# nrf9120_mlm1 register map
Vendor: Nordic Semiconductor; Series: nrf91; File version: 1
CPU: CM4 r0p1, little endian, MPU, FPU, 3 interrupt priority bits
Registers are 32-bit, read-write, reset 0x0 unless marked. A register's access mark holds for its fields unless they carry their own. Offsets are from the block's base; [hi:lo] are bit positions; lines under a group give offsets from that group; {n}, {i} and the like mark numbered series; 'fields as' and 'values as' point back to an identical list.

## DCNF — Domain Configuration Management
Base 0x40000000; alternate view of AMLI
0x420 CPUID ro — CPU number in the system
  [7:0] CPUID
0x440 EXTPERI0 group — Unspecified
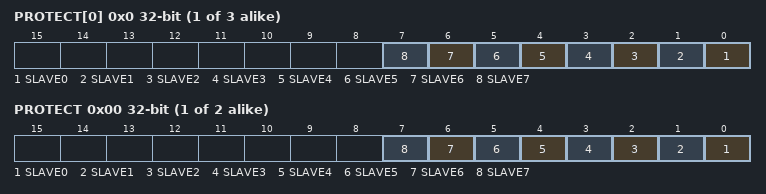
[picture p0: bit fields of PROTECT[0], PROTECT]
  {0x0+4j} PROTECT[{j}] (j=0..2) — Description collection: Control access for Master connected to AMLI master port EXTPERI[n]
    [all] fields
      0=Allowed (Access to slave is possible); 1=Blocked (Access to slave is blocked)
    [n] SLAVE{n} (n=0..7) — Control access to slave {n} of master EXTPERI[n].
0x460 EXTRAM group — Unspecified
  {0x0+4j} PROTECT[{j}] (j=0..2) — Description collection: Control access from Master connected to AMLI master port EXTRAM[n]
    [all] fields
      values as the fields of EXTPERI0.PROTECT[0]
    [n] SLAVE{n} (n=0..7) — Control access to slave {n} of master EXTRAM[n].
{0x480+4i} EXTCODE[{i}] (i=0..1) group — Unspecified
  0x00 PROTECT — Description cluster: Control access from Master connected to AMLI master port EXTCODE[n]
    [all] fields
      values as the fields of EXTPERI0.PROTECT[0]
    [n] SLAVE{n} (n=0..7) — Control access to slave {n} of master EXTCODE[n].

## GPIO — GPIO Port
Base 0x40800000
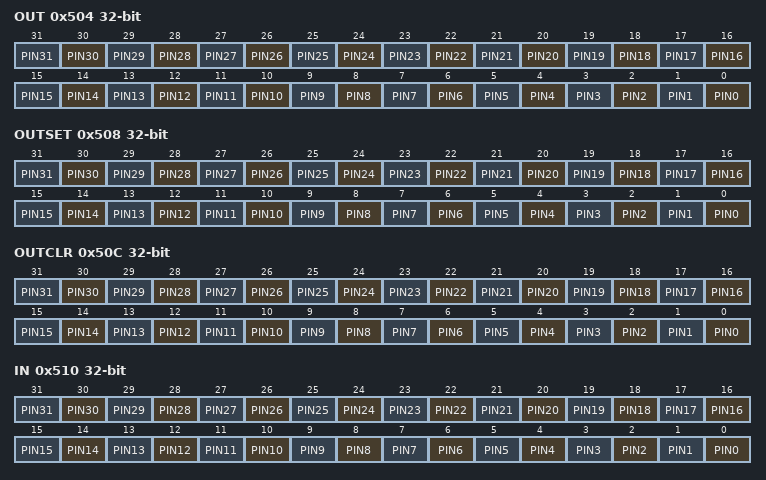
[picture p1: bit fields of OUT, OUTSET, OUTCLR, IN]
0x504 OUT — Write GPIO port
  [all] fields
    0=Low (Pin driver is low); 1=High (Pin driver is high)
  [n] PIN{n} (n=0..31)
0x508 OUTSET write-1-sets — Set individual bits in GPIO port
  [all] fields
    on read: 0=Low (Read: pin driver is low); 1=High (Read: pin driver is high) | on write: 1=Set (Write: writing a '1' sets the pin high; writing a '0' has no effect)
  [n] PIN{n} (n=0..31)
0x50C OUTCLR write-1-clears — Clear individual bits in GPIO port
  [all] fields
    on read: 0=Low (Read: pin driver is low); 1=High (Read: pin driver is high) | on write: 1=Clear (Write: writing a '1' sets the pin low; writing a '0' has no effect)
  [n] PIN{n} (n=0..31)
0x510 IN ro — Read GPIO port
  [all] fields
    0=Low (Pin input is low); 1=High (Pin input is high)
  [n] PIN{n} (n=0..31)
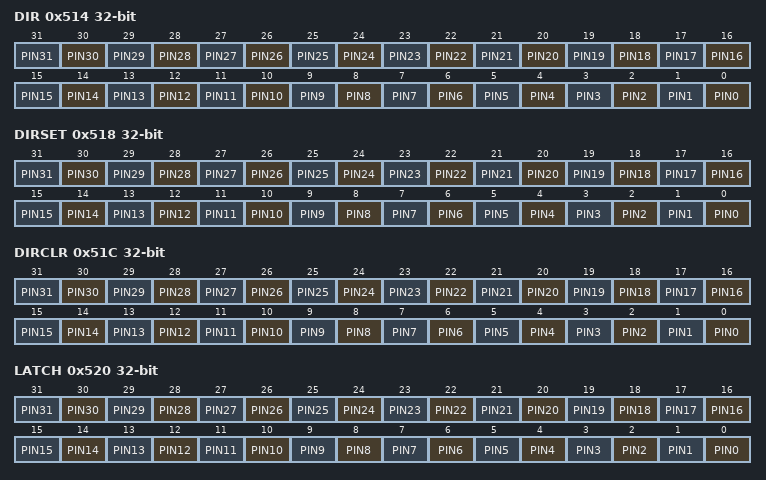
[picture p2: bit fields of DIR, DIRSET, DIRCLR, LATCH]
0x514 DIR — Direction of GPIO pins
  [all] fields
    0=Input (Pin set as input); 1=Output (Pin set as output)
  [n] PIN{n} (n=0..31)
0x518 DIRSET write-1-sets
  [all] fields
    on read: 0=Input (Read: pin set as input); 1=Output (Read: pin set as output) | on write: 1=Set (Write: writing a '1' sets pin to output; writing a '0' has no effect)
  [n] PIN{n} (n=0..31) — Set as output pin {n}
0x51C DIRCLR write-1-clears — DIR clear register
  [all] fields
    on read: 0=Input (Read: pin set as input); 1=Output (Read: pin set as output) | on write: 1=Clear (Write: writing a '1' sets pin to input; writing a '0' has no effect)
  [n] PIN{n} (n=0..31) — Set as input pin {n}
0x520 LATCH — Latch register indicating what GPIO pins that have met the criteria set in the PIN_CNF[n].SENSE registers
  [all] fields
    0=NotLatched (Criteria has not been met); 1=Latched (Criteria has been met)
  [n] PIN{n} (n=0..31) — Status on whether PIN{n} has met criteria set in PIN_CNF{n}.SENSE register. Write '1' to clear.
0x524 DETECTMODE — Select between default DETECT signal behaviour and LDETECT mode
  [0] DETECTMODE
    0=Default (DETECT directly connected to PIN DETECT signals); 1=LDETECT (Use the latched LDETECT behaviour)
{0x600+8i} PIN[{i}] (i=0..31) group — Pin n direct access
  0x00 OUT — Description cluster: Pin n direct access output register
    [0] OUT — Direct access
  0x04 IN — Description cluster: Pin n direct access input register
    [0] IN — Direct access
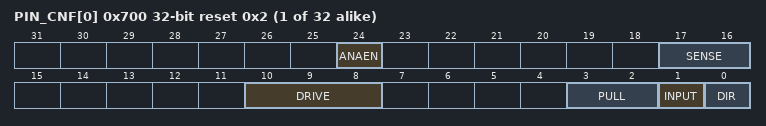
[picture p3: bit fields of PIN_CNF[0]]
{0x700+4i} PIN_CNF[{i}] (i=0..31) reset 0x2 — Description collection: Configuration of GPIO pins
  [24] ANAEN — Override of analog mux enable signals for pads with analog functionality
    0=Disabled (Override of analog mux is disabled); 1=AE0 (Enable analog signal 0 (analog test bus))
  [17:16] SENSE — Pin sensing mechanism
    0=Disabled; 2=High (Sense for high level); 3=Low (Sense for low level)
  [10:8] DRIVE — Drive configuration
    0=S0S1 (Standard '0', standard '1'); 1=H0S1 (High drive '0', standard '1'); 2=S0H1 (Standard '0', high drive '1'); 3=H0H1 (High drive '0', high 'drive '1''); 4=D0S1 (Disconnect '0' standard '1' (normally used for wired-or connections)); 5=D0H1 (Disconnect '0', high drive '1' (normally used for wired-or connections)); 6=S0D1 (Standard '0'. disconnect '1' (normally used for wired-and connections)); 7=H0D1 (High drive '0', disconnect '1' (normally used for wired-and connections))
  [3:2] PULL — Pull configuration
    0=Disabled (No pull); 1=Pull down on pin; 3=Pull up on pin
  [1] INPUT — Connect or disconnect input buffer
    0=Connect input buffer; 1=Disconnect input buffer
  [0] DIR — Pin direction. Same physical register as DIR register
    0=Input (Configure pin as an input pin); 1=Output (Configure pin as an output pin)

## Notices in the file
Copyright (c) 2016, Nordic Semiconductor ASA
All rights reserved.
Redistribution and use in source and binary forms, with or without
modification, are permitted provided that the following conditions are met:
Redistributions of source code must retain the above copyright notice, this
list of conditions and the following disclaimer.
Redistributions in binary form must reproduce the above copyright notice,
this list of conditions and the following disclaimer in the documentation
and/or other materials provided with the distribution.
Neither the name of Nordic Semiconductor ASA nor the names of its
contributors may be used to endorse or promote products derived from
this software without specific prior written permission.
THIS SOFTWARE IS PROVIDED BY THE COPYRIGHT HOLDERS AND CONTRIBUTORS "AS IS"
AND ANY EXPRESS OR IMPLIED WARRANTIES, INCLUDING, BUT NOT LIMITED TO, THE
IMPLIED WARRANTIES OF MERCHANTABILITY AND FITNESS FOR A PARTICULAR PURPOSE ARE
DISCLAIMED. IN NO EVENT SHALL THE COPYRIGHT HOLDER OR CONTRIBUTORS BE LIABLE
FOR ANY DIRECT, INDIRECT, INCIDENTAL, SPECIAL, EXEMPLARY, OR CONSEQUENTIAL
DAMAGES (INCLUDING, BUT NOT LIMITED TO, PROCUREMENT OF SUBSTITUTE GOODS OR
SERVICES; LOSS OF USE, DATA, OR PROFITS; OR BUSINESS INTERRUPTION) HOWEVER
CAUSED AND ON ANY THEORY OF LIABILITY, WHETHER IN CONTRACT, STRICT LIABILITY,
OR TORT (INCLUDING NEGLIGENCE OR OTHERWISE) ARISING IN ANY WAY OUT OF THE USE
OF THIS SOFTWARE, EVEN IF ADVISED OF THE POSSIBILITY OF SUCH DAMAGE.
